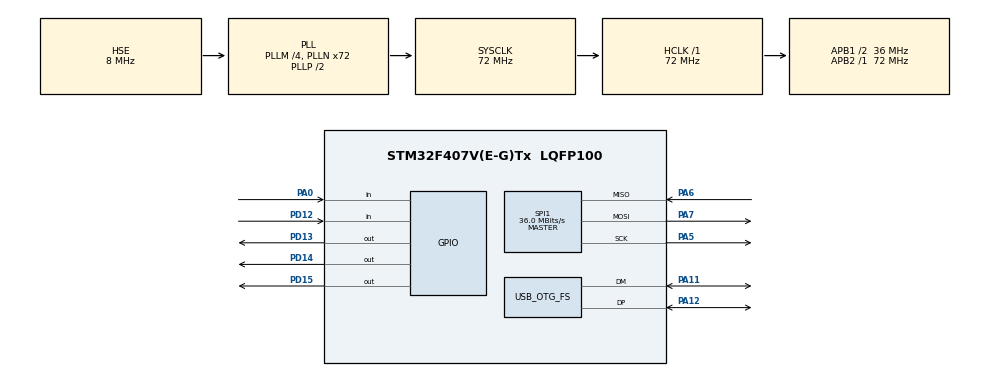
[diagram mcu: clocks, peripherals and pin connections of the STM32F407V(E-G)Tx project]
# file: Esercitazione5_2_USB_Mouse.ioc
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Mcu.Family=STM32F4
Mcu.Name=STM32F407V(E-G)Tx
Mcu.Package=LQFP100
NVIC.OTG_FS_IRQn=true\:0\:0\:false\:false\:true
NVIC.PriorityGroup=NVIC_PRIORITYGROUP_0
PA0-WKUP.Signal=GPIO_Input
PA11.Mode=Device_Only
PA11.Signal=USB_OTG_FS_DM
PA12.Mode=Device_Only
PA12.Signal=USB_OTG_FS_DP
PA13.Mode=Serial_Wire
PA13.Signal=SYS_JTMS-SWDIO
PA14.Mode=Serial_Wire
PA14.Signal=SYS_JTCK-SWCLK
PA5.Mode=Full_Duplex_Master
PA5.Signal=SPI1_SCK
PA6.Mode=Full_Duplex_Master
PA6.Signal=SPI1_MISO
PA7.Mode=Full_Duplex_Master
PA7.Signal=SPI1_MOSI
PD12.Signal=GPIO_Input
PD13.Signal=GPIO_Output
PD14.Signal=GPIO_Output
PD15.Signal=GPIO_Output
PH0-OSC_IN.Mode=HSE-External-Oscillator
PH0-OSC_IN.Signal=RCC_OSC_IN
PH1-OSC_OUT.Mode=HSE-External-Oscillator
PH1-OSC_OUT.Signal=RCC_OSC_OUT
ProjectManager.HeapSize=0x200
ProjectManager.StackSize=0x400
ProjectManager.TargetToolchain=SW4STM32
RCC.48MHZClocksFreq_Value=48000000
RCC.AHBFreq_Value=72000000
RCC.APB1CLKDivider=RCC_HCLK_DIV2
RCC.APB1Freq_Value=36000000
RCC.APB1TimFreq_Value=72000000
RCC.APB2Freq_Value=72000000
RCC.APB2TimFreq_Value=72000000
RCC.CortexFreq_Value=72000000
RCC.HCLKFreq_Value=72000000
RCC.HSE_VALUE=8000000
RCC.HSI_VALUE=16000000
RCC.LSE_VALUE=32768
RCC.PLLM=4
RCC.PLLN=72
RCC.PLLQ=3
RCC.SYSCLKFreq_VALUE=72000000
RCC.SYSCLKSource=RCC_SYSCLKSOURCE_PLLCLK
RCC.VCOOutputFreq_Value=144000000
SPI1.CalculateBaudRate=36.0 MBits/s
SPI1.Direction=SPI_DIRECTION_2LINES
SPI1.Mode=SPI_MODE_MASTER
SPI1.VirtualType=VM_MASTER
USB_DEVICE.CLASS_NAME_FS=HID
USB_DEVICE.VirtualModeFS=Hid_FS
USB_OTG_FS.VirtualMode=Device_Only
VP_USB_DEVICE_VS_USB_DEVICE_HID_FS.Mode=HID_FS
board=STM32F4DISCOVERY

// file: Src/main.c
#include "main.h"
#include "stm32f4xx_hal.h"
#include "usb_device.h"
#include "usbd_hid.h"

/* USER CODE BEGIN Includes */
#include "mouse_position.h"
/* USER CODE END Includes */

SPI_HandleTypeDef hspi1;
extern USBD_HandleTypeDef hUsbDeviceFS;

/* USER CODE BEGIN PV */
/* Private variables ---------------------------------------------------------*/

/* USER CODE END PV */

void SystemClock_Config(void);
static void MX_GPIO_Init(void);
static void MX_SPI1_Init(void);

/* USER CODE BEGIN PFP */
/* Private function prototypes -----------------------------------------------*/

/* USER CODE END PFP */
uint8_t USB_TX_Buffer[4];

int main(void)
{

  /* MCU Configuration----------------------------------------------------------*/

  /* Reset of all peripherals, Initializes the Flash interface and the Systick. */
  HAL_Init();

  /* Configure the system clock */
  SystemClock_Config();

  /* Initialize all configured peripherals */
  MX_GPIO_Init();
  MX_SPI1_Init();
  MX_USB_DEVICE_Init();
  /*Inizializzazione device*/
  init_mouse(hspi1);
  uint8_t x_prev=0;
  uint8_t y_prev=0;
  /*Loop infinito per gestione posizione puntatore e tasto sinistro*/
  while (1)
  {
  	  /*Si legge valore tasto sinistro*/
	  USB_TX_Buffer[0]=HAL_GPIO_ReadPin(GPIOA,GPIO_PIN_0);

	  /*Lettura coordinata X*/
	  USB_TX_Buffer[1]=x_position(hspi1);

	  /*Lettura coordinata Y*/
	  USB_TX_Buffer[2]=y_position(hspi1);

	  /*Byte lasciato inutilizzato*/
	  USB_TX_Buffer[3]=0x00;

	  /*Se la soglia di spostamento è superata allora vengono inviati i 4 byte necessari
	   * allo spostamento del puntatore*/
	  if(USB_TX_Buffer[1]-x_prev>0.25 || USB_TX_Buffer[1]-x_prev<-0.25){
		 if(USB_TX_Buffer[2]-y_prev>0.25 || USB_TX_Buffer[2]-y_prev<-0.25){
			  USBD_HID_SendReport(&hUsbDeviceFS,USB_TX_Buffer,4);

			  /*Illuminazione led in base allo spostamento*/
			  position_on_led(USB_TX_Buffer[1],X);
			  position_on_led(USB_TX_Buffer[2],Y);
		  }
	  }
	  x_prev=USB_TX_Buffer[1];
	  y_prev=USB_TX_Buffer[2];
	  HAL_Delay(5);
  }

}

/** System Clock Configuration
*/
void SystemClock_Config(void)
{

  RCC_OscInitTypeDef RCC_OscInitStruct;
  RCC_ClkInitTypeDef RCC_ClkInitStruct;

    /**Configure the main internal regulator output voltage
    */
  __HAL_RCC_PWR_CLK_ENABLE();

  __HAL_PWR_VOLTAGESCALING_CONFIG(PWR_REGULATOR_VOLTAGE_SCALE1);

    /**Initializes the CPU, AHB and APB busses clocks
    */
  RCC_OscInitStruct.OscillatorType = RCC_OSCILLATORTYPE_HSE;
  RCC_OscInitStruct.HSEState = RCC_HSE_ON;
  RCC_OscInitStruct.PLL.PLLState = RCC_PLL_ON;
  RCC_OscInitStruct.PLL.PLLSource = RCC_PLLSOURCE_HSE;
  RCC_OscInitStruct.PLL.PLLM = 4;
  RCC_OscInitStruct.PLL.PLLN = 72;
  RCC_OscInitStruct.PLL.PLLP = RCC_PLLP_DIV2;
  RCC_OscInitStruct.PLL.PLLQ = 3;
  if (HAL_RCC_OscConfig(&RCC_OscInitStruct) != HAL_OK)
  {
    _Error_Handler(__FILE__, __LINE__);
  }

    /**Initializes the CPU, AHB and APB busses clocks
    */
  RCC_ClkInitStruct.ClockType = RCC_CLOCKTYPE_HCLK|RCC_CLOCKTYPE_SYSCLK
                              |RCC_CLOCKTYPE_PCLK1|RCC_CLOCKTYPE_PCLK2;
  RCC_ClkInitStruct.SYSCLKSource = RCC_SYSCLKSOURCE_PLLCLK;
  RCC_ClkInitStruct.AHBCLKDivider = RCC_SYSCLK_DIV1;
  RCC_ClkInitStruct.APB1CLKDivider = RCC_HCLK_DIV2;
  RCC_ClkInitStruct.APB2CLKDivider = RCC_HCLK_DIV1;

  if (HAL_RCC_ClockConfig(&RCC_ClkInitStruct, FLASH_LATENCY_2) != HAL_OK)
  {
    _Error_Handler(__FILE__, __LINE__);
  }

    /**Configure the Systick interrupt time
    */
  HAL_SYSTICK_Config(HAL_RCC_GetHCLKFreq()/1000);

    /**Configure the Systick
    */
  HAL_SYSTICK_CLKSourceConfig(SYSTICK_CLKSOURCE_HCLK);

  /* SysTick_IRQn interrupt configuration */
  HAL_NVIC_SetPriority(SysTick_IRQn, 0, 0);
}

/* SPI1 init function */
static void MX_SPI1_Init(void)
{

  hspi1.Instance = SPI1;
  hspi1.Init.Mode = SPI_MODE_MASTER;
  hspi1.Init.Direction = SPI_DIRECTION_2LINES;
  hspi1.Init.DataSize = SPI_DATASIZE_8BIT;
  hspi1.Init.CLKPolarity = SPI_POLARITY_LOW;
  hspi1.Init.CLKPhase = SPI_PHASE_1EDGE;
  hspi1.Init.NSS = SPI_NSS_SOFT;
  hspi1.Init.BaudRatePrescaler = SPI_BAUDRATEPRESCALER_8;
  hspi1.Init.FirstBit = SPI_FIRSTBIT_MSB;
  hspi1.Init.TIMode = SPI_TIMODE_DISABLE;
  hspi1.Init.CRCCalculation = SPI_CRCCALCULATION_DISABLE;
  hspi1.Init.CRCPolynomial = 10;
  if (HAL_SPI_Init(&hspi1) != HAL_OK)
  {
    _Error_Handler(__FILE__, __LINE__);
  }

}

/** Configure pins as
        * Analog
        * Input
        * Output
        * EVENT_OUT
        * EXTI
*/
static void MX_GPIO_Init(void)
{

  GPIO_InitTypeDef GPIO_InitStruct;

  /* GPIO Ports Clock Enable */
  __HAL_RCC_GPIOE_CLK_ENABLE();
  __HAL_RCC_GPIOH_CLK_ENABLE();
  __HAL_RCC_GPIOA_CLK_ENABLE();
  __HAL_RCC_GPIOD_CLK_ENABLE();

  /*Configure GPIO pin Output Level */
  HAL_GPIO_WritePin(GPIOE, GPIO_PIN_3, GPIO_PIN_RESET);

  /*Configure GPIO pin Output Level */
  HAL_GPIO_WritePin(GPIOD, GPIO_PIN_12|GPIO_PIN_13|GPIO_PIN_14|GPIO_PIN_15, GPIO_PIN_RESET);

  /*Configure GPIO pin : PE3 */
  GPIO_InitStruct.Pin = GPIO_PIN_3;
  GPIO_InitStruct.Mode = GPIO_MODE_OUTPUT_PP;
  GPIO_InitStruct.Pull = GPIO_NOPULL;
  GPIO_InitStruct.Speed = GPIO_SPEED_FREQ_LOW;
  HAL_GPIO_Init(GPIOE, &GPIO_InitStruct);

  /*Configure GPIO pin : PA0 */
  GPIO_InitStruct.Pin = GPIO_PIN_0;
  GPIO_InitStruct.Mode = GPIO_MODE_INPUT;
  GPIO_InitStruct.Pull = GPIO_NOPULL;
  HAL_GPIO_Init(GPIOA, &GPIO_InitStruct);

  /*Configure GPIO pins : PD12 PD13 PD14 PD15 */
  GPIO_InitStruct.Pin = GPIO_PIN_12|GPIO_PIN_13|GPIO_PIN_14|GPIO_PIN_15;
  GPIO_InitStruct.Mode = GPIO_MODE_OUTPUT_PP;
  GPIO_InitStruct.Pull = GPIO_NOPULL;
  GPIO_InitStruct.Speed = GPIO_SPEED_FREQ_LOW;
  HAL_GPIO_Init(GPIOD, &GPIO_InitStruct);

}

void _Error_Handler(char * file, int line)
{
  while(1)
  {
  }
}

/************************ (C) COPYRIGHT STMicroelectronics *****END OF FILE****/
